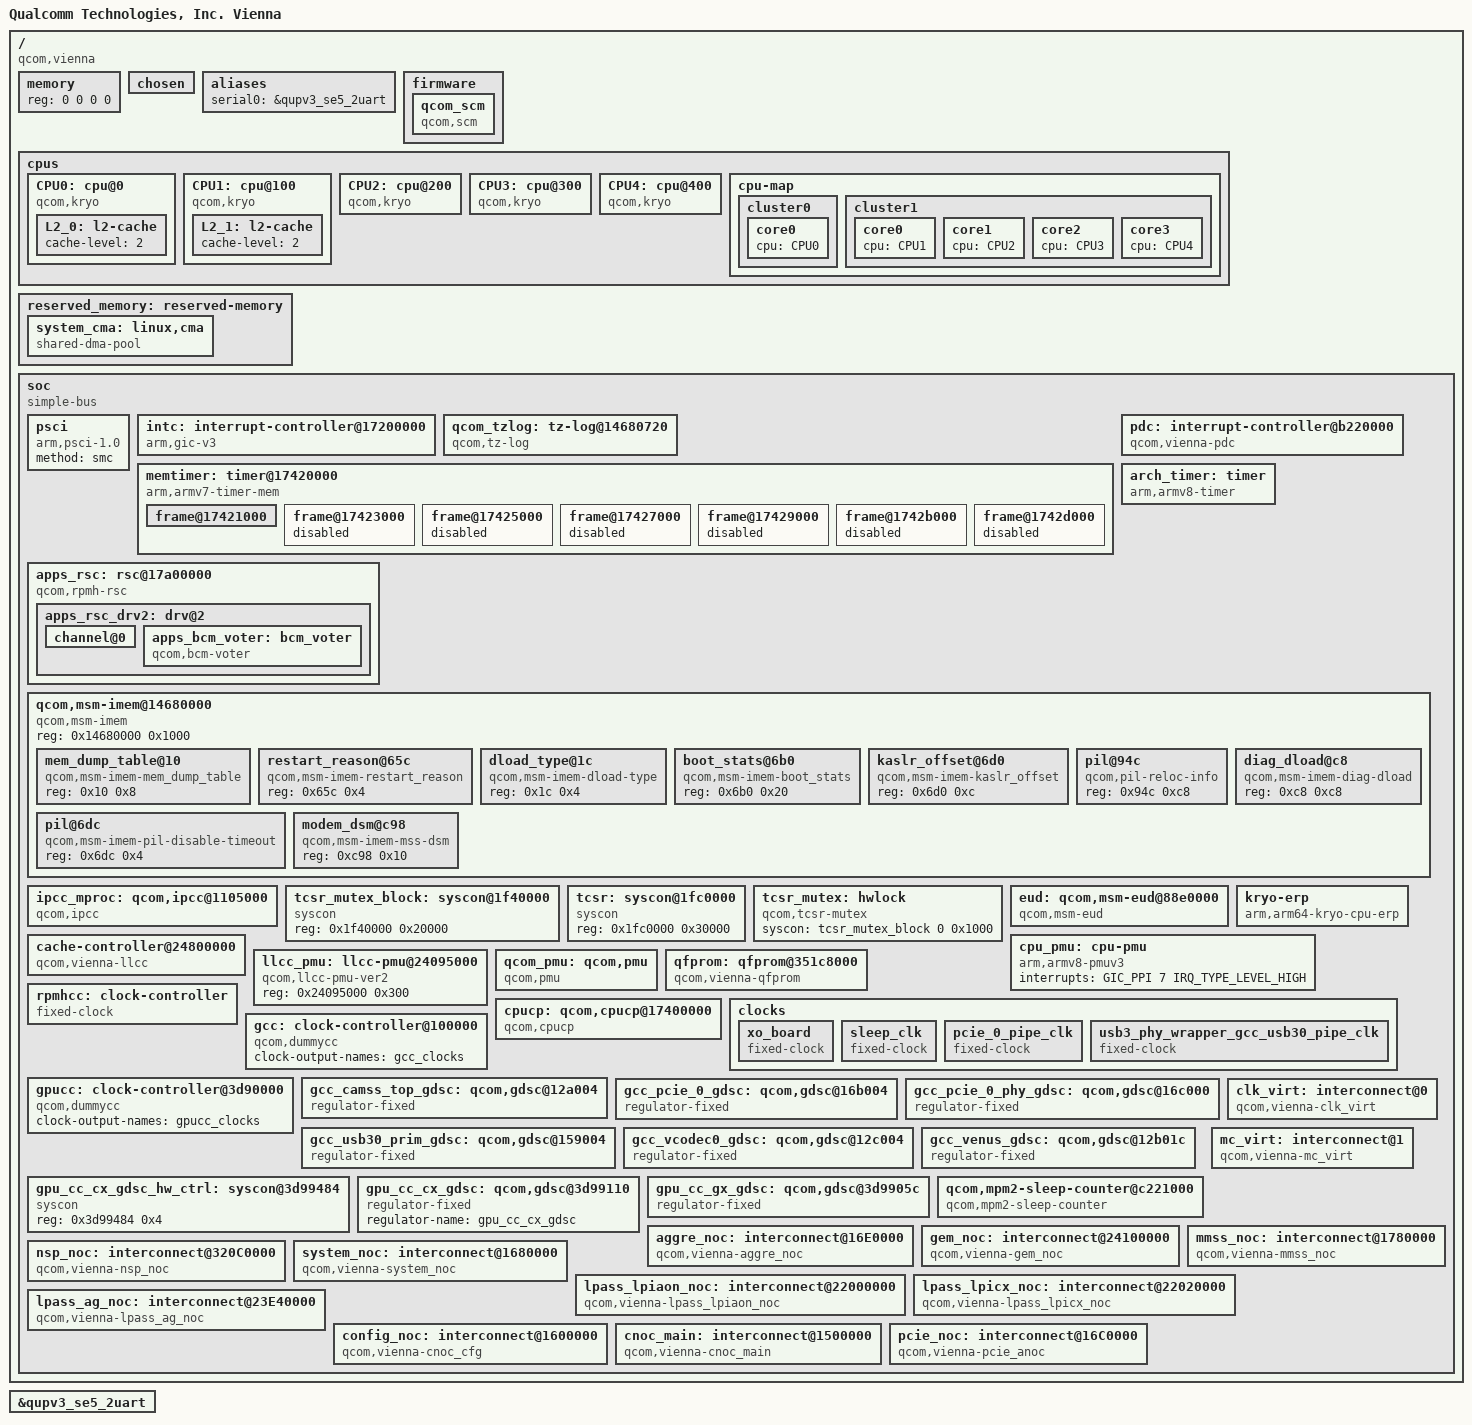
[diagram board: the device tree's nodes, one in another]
// SPDX-License-Identifier: BSD-3-Clause
/*
 * Copyright (c) 2024-2025 Qualcomm Innovation Center, Inc. All rights reserved.
 */

#include <dt-bindings/clock/qcom,gcc-vienna.h>
#include <dt-bindings/clock/qcom,gpucc-vienna.h>
#include <dt-bindings/clock/qcom,rpmh.h>
#include <dt-bindings/interrupt-controller/arm-gic.h>
#include <dt-bindings/interconnect/qcom,icc.h>
#include <dt-bindings/interconnect/qcom,vienna.h>
#include <dt-bindings/soc/qcom,rpmh-rsc.h>
#include <dt-bindings/regulator/qcom,rpmh-regulator-levels.h>

/ {
	model = "Qualcomm Technologies, Inc. Vienna";
	compatible = "qcom,vienna";
	qcom,msm-id = <669 0x10000 >;
	interrupt-parent = <&intc>;
	#address-cells = <2>;
	#size-cells = <2>;
	memory { device_type = "memory"; reg = <0 0 0 0>; };

	chosen: chosen {
		bootargs = "earlycon=qcom_geni,0xa94000 kasan=off nokaslr kpti=0 log_buf_len=256K swiotlb=0 loop.max_part=7";
	};

	aliases {
		serial0 = &qupv3_se5_2uart;
	};

	firmware: firmware {
		qcom_scm: qcom_scm { };
	 };

	cpus {
		#address-cells = <2>;
		#size-cells = <0>;
		CPU0: cpu@0 {
			device_type = "cpu";
			compatible = "qcom,kryo";
			reg = <0x0 0x0>;
			enable-method = "psci";
			cpu-release-addr = <0x0 0x90000000>;
			next-level-cache = <&L2_0>;
			L2_0: l2-cache {
			      cache-level = <2>;
			};
		};

		CPU1: cpu@100 {
			device_type = "cpu";
			compatible = "qcom,kryo";
			reg = <0x0 0x100>;
			enable-method = "psci";
			cpu-release-addr = <0x0 0x90000000>;
			next-level-cache = <&L2_1>;
			L2_1: l2-cache {
			      cache-level = <2>;
			};

		};

		CPU2: cpu@200 {
			device_type = "cpu";
			compatible = "qcom,kryo";
			reg = <0x0 0x200>;
			enable-method = "psci";
			cpu-release-addr = <0x0 0x90000000>;
			next-level-cache = <&L2_1>;
		};

		CPU3: cpu@300 {
			device_type = "cpu";
			compatible = "qcom,kryo";
			reg = <0x0 0x300>;
			enable-method = "psci";
			cpu-release-addr = <0x0 0x90000000>;
			next-level-cache = <&L2_1>;
		};

		CPU4: cpu@400 {
			device_type = "cpu";
			compatible = "qcom,kryo";
			reg = <0x0 0x400>;
			enable-method = "psci";
			cpu-release-addr = <0x0 0x90000000>;
			next-level-cache = <&L2_1>;
		};

		cpu-map {
			cluster0 {
				core0 {
					cpu = <&CPU0>;
				};

			};

			cluster1 {
				core0 {
					cpu = <&CPU1>;
				};

				core1 {
					cpu = <&CPU2>;
				};

				core2 {
					cpu = <&CPU3>;
				};

				core3 {
					cpu = <&CPU4>;
				};

			};

		};

	};

	reserved_memory: reserved-memory { };

	soc: soc { };
};

&qcom_scm {
	compatible = "qcom,scm";
};

&soc {
	#address-cells = <1>;
	#size-cells = <1>;
	ranges = <0 0 0 0xffffffff>;
	compatible = "simple-bus";

	psci {
		compatible = "arm,psci-1.0";
		method = "smc";
	};

	intc: interrupt-controller@17200000 {
		compatible = "arm,gic-v3";
		#interrupt-cells = <3>;
		interrupt-controller;
		#redistributor-regions = <1>;
		redistributor-stride = <0x0 0x20000>;
		reg = <0x17200000 0x10000>,	// GICD
		      <0x17260000 0xA0000>;	// GICR * 5
		interrupts = <GIC_PPI 9 IRQ_TYPE_LEVEL_HIGH>;
	};

	qcom_tzlog: tz-log@14680720 {
		compatible = "qcom,tz-log";
		reg = <0x14680720 0x3000>;
		qcom,hyplog-enabled;
		hyplog-address-offset = <0x410>;
		hyplog-size-offset = <0x414>;
	};

	memtimer: timer@17420000 {
		#address-cells = <1>;
		#size-cells = <1>;
		ranges;
		compatible = "arm,armv7-timer-mem";
		reg = <0x17420000 0x1000>;
		clock-frequency = <19200000>;
		frame@17421000 {
			frame-number = <0>;
			interrupts = <GIC_SPI 8 IRQ_TYPE_LEVEL_HIGH>,
				     <GIC_SPI 6 IRQ_TYPE_LEVEL_HIGH>;
			reg = <0x17421000 0x1000>,
			      <0x17422000 0x1000>;
		};

		frame@17423000 {
			frame-number = <1>;
			interrupts = <GIC_SPI 9 IRQ_TYPE_LEVEL_HIGH>;
			reg = <0x17423000 0x1000>;
			status = "disabled";
		};

		frame@17425000 {
			frame-number = <2>;
			interrupts = <GIC_SPI 10 IRQ_TYPE_LEVEL_HIGH>;
			reg = <0x17425000 0x1000>;
			status = "disabled";
		};

		frame@17427000 {
			frame-number = <3>;
			interrupts = <GIC_SPI 11 IRQ_TYPE_LEVEL_HIGH>;
			reg = <0x17427000 0x1000>;
			status = "disabled";
		};

		frame@17429000 {
			frame-number = <4>;
			interrupts = <GIC_SPI 12 IRQ_TYPE_LEVEL_HIGH>;
			reg = <0x17429000 0x1000>;
			status = "disabled";
		};

		frame@1742b000 {
			frame-number = <5>;
			interrupts = <GIC_SPI 13 IRQ_TYPE_LEVEL_HIGH>;
			reg = <0x1742b000 0x1000>;
			status = "disabled";
		};

		frame@1742d000 {
			frame-number = <6>;
			interrupts = <GIC_SPI 14 IRQ_TYPE_LEVEL_HIGH>;
			reg = <0x1742d000 0x1000>;
			status = "disabled";
		};
	};

	apps_rsc: rsc@17a00000 {
		label = "apps_rsc";
		compatible = "qcom,rpmh-rsc";
		reg = <0x17a00000 0x10000>,
		      <0x17a10000 0x10000>,
		      <0x17a20000 0x10000>;
		reg-names = "drv-0", "drv-1", "drv-2";
		qcom,drv-count = <3>;
		interrupts = <GIC_SPI 3 IRQ_TYPE_LEVEL_HIGH>,
			     <GIC_SPI 4 IRQ_TYPE_LEVEL_HIGH>,
			     <GIC_SPI 5 IRQ_TYPE_LEVEL_HIGH>;

		apps_rsc_drv2: drv@2 {
			qcom,drv-id = <2>;
			qcom,tcs-offset = <0xd00>;
			qcom,tcs-distance = <0x2a0>;
			channel@0 {
				qcom,tcs-config = <ACTIVE_TCS    3>,
						  <SLEEP_TCS     2>,
						  <WAKE_TCS      2>,
						  <CONTROL_TCS   0>,
						  <FAST_PATH_TCS 1>;
			};

			apps_bcm_voter: bcm_voter {
				compatible = "qcom,bcm-voter";
			};
		};
	};

	pdc: interrupt-controller@b220000 {
		compatible = "qcom,vienna-pdc", "qcom,pdc";
		reg = <0xb220000 0x10000>, <0x174000f0 0x64>;
		qcom,pdc-ranges = <0 456 30>, <38 663 9>, <51 527 47>,
				  <98 608 32>, <130 716 12>, <142 251 5>,
				  <147 584 16>;
		#interrupt-cells = <2>;
		interrupt-parent = <&intc>;
		interrupt-controller;
	};

	arch_timer: timer {
		compatible = "arm,armv8-timer";
		interrupts = <GIC_PPI 13 (GIC_CPU_MASK_SIMPLE(8) | IRQ_TYPE_LEVEL_LOW)>,
			     <GIC_PPI 14 (GIC_CPU_MASK_SIMPLE(8) | IRQ_TYPE_LEVEL_LOW)>,
			     <GIC_PPI 11 (GIC_CPU_MASK_SIMPLE(8) | IRQ_TYPE_LEVEL_LOW)>,
			     <GIC_PPI 12 (GIC_CPU_MASK_SIMPLE(8) | IRQ_TYPE_LEVEL_LOW)>;
		clock-frequency = <19200000>;
	};

	qcom,msm-imem@14680000 {
		compatible = "qcom,msm-imem";
		reg = <0x14680000 0x1000>;
		ranges = <0x0 0x14680000 0x1000>;
		#address-cells = <1>;
		#size-cells = <1>;

		mem_dump_table@10 {
			compatible = "qcom,msm-imem-mem_dump_table";
			reg = <0x10 0x8>;
		};

		restart_reason@65c {
			compatible = "qcom,msm-imem-restart_reason";
			reg = <0x65c 0x4>;
		};

		dload_type@1c {
			compatible = "qcom,msm-imem-dload-type";
			reg = <0x1c 0x4>;
		};

		boot_stats@6b0 {
			compatible = "qcom,msm-imem-boot_stats";
			reg = <0x6b0 0x20>;
		};

		kaslr_offset@6d0 {
			compatible = "qcom,msm-imem-kaslr_offset";
			reg = <0x6d0 0xc>;
		};

		pil@94c {
			compatible = "qcom,pil-reloc-info";
			reg = <0x94c 0xc8>;
		};

		pil@6dc {
			compatible = "qcom,msm-imem-pil-disable-timeout";
			reg = <0x6dc 0x4>;
		};

		diag_dload@c8 {
			compatible = "qcom,msm-imem-diag-dload";
			reg = <0xc8 0xc8>;
		};

		modem_dsm@c98 {
			compatible = "qcom,msm-imem-mss-dsm";
			reg = <0xc98 0x10>;
		};
	};

	ipcc_mproc: qcom,ipcc@1105000 {
		compatible = "qcom,ipcc";
		reg = <0x01105000 0x1000>;
		interrupts = <GIC_SPI 366 IRQ_TYPE_LEVEL_HIGH>;
		interrupt-controller;
		#interrupt-cells = <3>;
		#mbox-cells = <2>;
	};

	tcsr_mutex_block: syscon@1f40000 {
		compatible = "syscon";
		reg = <0x1f40000 0x20000>;
	};

	tcsr: syscon@1fc0000 {
		compatible = "syscon";
		reg = <0x1fc0000 0x30000>;
	};

	tcsr_mutex: hwlock {
		compatible = "qcom,tcsr-mutex";
		syscon = <&tcsr_mutex_block 0 0x1000>;
		#hwlock-cells = <1>;
	};

	eud: qcom,msm-eud@88e0000 {
		compatible = "qcom,msm-eud";
		interrupt-names = "eud_irq";
		/*interrupt-parent = <&pdc>;*/
		interrupts = <GIC_SPI 473 IRQ_TYPE_LEVEL_HIGH>;
		reg = <0x88e0000 0x2000>,
			<0x88e2000 0x1000>;
		reg-names = "eud_base", "eud_mode_mgr2";
		qcom,secure-eud-en;
		status = "ok";
	};

	cache-controller@24800000 {
		compatible = "qcom,vienna-llcc";
		reg = <0x24800000 0x200000>;
		reg-names = "llcc0_base";
		interrupts = <GIC_SPI 266 IRQ_TYPE_LEVEL_HIGH>;
		cap-based-alloc-and-pwr-collapse;
	};

	kryo-erp {
		compatible = "arm,arm64-kryo-cpu-erp";
		interrupts = <GIC_PPI 0 IRQ_TYPE_LEVEL_HIGH>,
			<GIC_SPI 35 IRQ_TYPE_LEVEL_HIGH>;
		interrupt-names = "l1-l2-faultirq","l3-scu-faultirq";
	};

	cpu_pmu: cpu-pmu {
		compatible = "arm,armv8-pmuv3";
		interrupts = <GIC_PPI 7 IRQ_TYPE_LEVEL_HIGH>;
	};

	llcc_pmu: llcc-pmu@24095000 {
		compatible = "qcom,llcc-pmu-ver2";
		reg = <0x24095000 0x300>;
		reg-names = "lagg-base";
	};

	qcom_pmu: qcom,pmu {
		compatible = "qcom,pmu";
		qcom,pmu-events-tbl =
			< 0x0008 0x3F 0xFF 0xFF >,
			< 0x0011 0x3F 0xFF 0xFF >,
			< 0x0017 0x3F 0xFF 0xFF >,
			< 0x002A 0x3F 0xFF 0xFF >,
			< 0x1000 0x3F 0xFF 0xFF >;
	};

	qfprom: qfprom@351c8000 {
		compatible = "qcom,vienna-qfprom", "qcom,qfprom";
		reg = <0x351c8000 0x1000>;
		#address-cells = <1>;
		#size-cells = <1>;
		read-only;
		ranges;
	};

	cpucp: qcom,cpucp@17400000 {
		#address-cells = <2>;
		#size-cells = <2>;
		compatible = "qcom,cpucp";
		reg = <0x17400000 0x10>,
			<0x17d90000 0x2000>;
		#mbox-cells = <1>;
		interrupts = <GIC_SPI 62 IRQ_TYPE_LEVEL_HIGH>;
	};

	clocks {
		xo_board: xo_board {
			compatible = "fixed-clock";
			clock-frequency = <19200000>;
			clock-output-names = "xo_board";
			#clock-cells = <0>;
		};

		sleep_clk: sleep_clk {
			compatible = "fixed-clock";
			clock-frequency = <32000>;
			clock-output-names = "sleep_clk";
			#clock-cells = <0>;
		};

		pcie_0_pipe_clk: pcie_0_pipe_clk {
			compatible = "fixed-clock";
			clock-frequency = <1000>;
			clock-output-names = "pcie_0_pipe_clk";
			#clock-cells = <0>;
		};

		usb3_phy_wrapper_gcc_usb30_pipe_clk: usb3_phy_wrapper_gcc_usb30_pipe_clk {
			compatible = "fixed-clock";
			clock-frequency = <1000>;
			clock-output-names = "usb3_phy_wrapper_gcc_usb30_pipe_clk";
			#clock-cells = <0>;
		};
	};

	rpmhcc: clock-controller {
		compatible = "fixed-clock";
		clock-output-names = "rpmh_clocks";
		clock-frequency = <19200000>;
		#clock-cells = <1>;
	};

	gcc: clock-controller@100000 {
		compatible = "qcom,dummycc";
		clock-output-names = "gcc_clocks";
		#clock-cells = <1>;
		#reset-cells = <1>;
	};

	gpucc: clock-controller@3d90000 {
		compatible = "qcom,dummycc";
		clock-output-names = "gpucc_clocks";
		#clock-cells = <1>;
		#reset-cells = <1>;
	};

	/* GCC GDSCs */
	gcc_camss_top_gdsc: qcom,gdsc@12a004 {
		compatible = "regulator-fixed";
		regulator-name = "gcc_camss_top_gdsc";
		qcom,support-cfg-gdscr;
	};

	gcc_pcie_0_gdsc: qcom,gdsc@16b004 {
		compatible = "regulator-fixed";
		regulator-name = "gcc_pcie_0_gdsc";
		qcom,support-cfg-gdscr;
	};

	gcc_pcie_0_phy_gdsc: qcom,gdsc@16c000 {
		compatible = "regulator-fixed";
		regulator-name = "gcc_pcie_0_phy_gdsc";
		qcom,support-cfg-gdscr;
	};

	gcc_usb30_prim_gdsc: qcom,gdsc@159004 {
		compatible = "regulator-fixed";
		regulator-name = "gcc_usb30_prim_gdsc";
		qcom,support-cfg-gdscr;
	};

	gcc_vcodec0_gdsc: qcom,gdsc@12c004 {
		compatible = "regulator-fixed";
		regulator-name = "gcc_vcodec0_gdsc";
		qcom,support-hw-trigger;
		qcom,support-cfg-gdscr;
	};

	gcc_venus_gdsc: qcom,gdsc@12b01c {
		compatible = "regulator-fixed";
		regulator-name = "gcc_venus_gdsc";
		qcom,support-cfg-gdscr;
	};

	/* GPU_CC GDSCs */
	gpu_cc_cx_gdsc_hw_ctrl: syscon@3d99484 {
		compatible = "syscon";
		reg = <0x3d99484 0x4>;
	};

	gpu_cc_cx_gdsc: qcom,gdsc@3d99110 {
		compatible = "regulator-fixed";
		regulator-name = "gpu_cc_cx_gdsc";
	};

	gpu_cc_gx_gdsc: qcom,gdsc@3d9905c {
		compatible = "regulator-fixed";
		regulator-name = "gpu_cc_gx_gdsc";
		qcom,support-cfg-gdscr;
	};

	qcom,mpm2-sleep-counter@c221000 {
		compatible = "qcom,mpm2-sleep-counter";
		reg = <0xc221000 0x1000>;
		clock-frequency = <32768>;
	};

	clk_virt: interconnect@0 {
		compatible = "qcom,vienna-clk_virt";
		#interconnect-cells = <1>;
		qcom,bcm-voter-names = "hlos";
		qcom,bcm-voters = <&apps_bcm_voter>;
		qcom,skip-qos;
	};

	mc_virt: interconnect@1 {
		compatible = "qcom,vienna-mc_virt";
		#interconnect-cells = <1>;
		qcom,bcm-voter-names = "hlos";
		qcom,bcm-voters = <&apps_bcm_voter>;
		qcom,skip-qos;
	};

	aggre_noc: interconnect@16E0000 {
		compatible = "qcom,vienna-aggre_noc";
		reg = <0x016E0000 0x1F400>;
		#interconnect-cells = <1>;
		qcom,bcm-voter-names = "hlos";
		qcom,bcm-voters = <&apps_bcm_voter>;
		qcom,skip-qos;
	};

	gem_noc: interconnect@24100000 {
		compatible = "qcom,vienna-gem_noc";
		reg = <0x24100000 0x17F080>;
		#interconnect-cells = <1>;
		qcom,bcm-voter-names = "hlos";
		qcom,bcm-voters = <&apps_bcm_voter>;
		qcom,skip-qos;
	};

	mmss_noc: interconnect@1780000 {
		compatible = "qcom,vienna-mmss_noc";
		reg = <0x01780000 0x5B400>;
		#interconnect-cells = <1>;
		qcom,bcm-voter-names = "hlos";
		qcom,bcm-voters = <&apps_bcm_voter>;
		qcom,skip-qos;
	};

	nsp_noc: interconnect@320C0000 {
		compatible = "qcom,vienna-nsp_noc";
		reg = <0x320C0000 0x1F400>;
		#interconnect-cells = <1>;
		qcom,bcm-voter-names = "hlos";
		qcom,bcm-voters = <&apps_bcm_voter>;
		qcom,skip-qos;
	};

	system_noc: interconnect@1680000 {
		compatible = "qcom,vienna-system_noc";
		reg = <0x01680000 0x40000>;
		#interconnect-cells = <1>;
		qcom,bcm-voter-names = "hlos";
		qcom,bcm-voters = <&apps_bcm_voter>;
		qcom,skip-qos;
	};

	lpass_lpiaon_noc: interconnect@22000000 {
		compatible = "qcom,vienna-lpass_lpiaon_noc";
		reg = <0x22000000 0x19080>;
		#interconnect-cells = <1>;
		qcom,bcm-voter-names = "hlos";
		qcom,bcm-voters = <&apps_bcm_voter>;
		qcom,skip-qos;
	};

	lpass_lpicx_noc: interconnect@22020000 {
		compatible = "qcom,vienna-lpass_lpicx_noc";
		reg = <0x22020000 0x5F400>;
		#interconnect-cells = <1>;
		qcom,bcm-voter-names = "hlos";
		qcom,bcm-voters = <&apps_bcm_voter>;
		qcom,skip-qos;
	};

	lpass_ag_noc: interconnect@23E40000 {
		compatible = "qcom,vienna-lpass_ag_noc";
		reg = <0x23E40000 0xE080>;
		#interconnect-cells = <1>;
		qcom,bcm-voter-names = "hlos";
		qcom,bcm-voters = <&apps_bcm_voter>;
		qcom,skip-qos;
	};

	config_noc: interconnect@1600000 {
		compatible = "qcom,vienna-cnoc_cfg";
		reg = <0x1600000 0x7400>;
		#interconnect-cells = <1>;
		qcom,bcm-voter-names = "hlos";
		qcom,bcm-voters = <&apps_bcm_voter>;
		qcom,skip-qos;
	};

	cnoc_main: interconnect@1500000 {
		compatible = "qcom,vienna-cnoc_main";
		reg = <0x01500000 0x16400>;
		#interconnect-cells = <1>;
		qcom,bcm-voter-names = "hlos";
		qcom,bcm-voters = <&apps_bcm_voter>;
		qcom,skip-qos;
	};

	pcie_noc: interconnect@16C0000 {
		compatible = "qcom,vienna-pcie_anoc";
		reg = <0x016C0000 0x11400>;
		#interconnect-cells = <1>;
		qcom,bcm-voter-names = "hlos";
		qcom,bcm-voters = <&apps_bcm_voter>;
		qcom,skip-qos;
	};
};

#include "vienna-dma-heaps.dtsi"
#include "vienna-pinctrl.dtsi"
#include "vienna-reserved-memory.dtsi"
#include "vienna-stub-regulators.dtsi"
#include "msm-arm-smmu-vienna.dtsi"
#include "vienna-qupv3.dtsi"
#include "vienna-usb.dtsi"

&reserved_memory {
	#address-cells = <2>;
	#size-cells = <2>;
	ranges;

	/* global autoconfigured region for contiguous allocations */
	system_cma: linux,cma {
		compatible = "shared-dma-pool";
		alloc-ranges = <0x0 0x00000000 0x0 0xffffffff>;
		reusable;
		alignment = <0x0 0x400000>;
		size = <0x0 0x1000000>;
		linux,cma-default;
	};
};

&qupv3_se5_2uart {
	status = "ok";
};

#include "ipcc-test-vienna.dtsi"
/delete-node/ &ipcc_self_ping_adsp;
/delete-node/ &ipcc_self_ping_cdsp;
/delete-node/ &ipcc_self_ping_slpi;
